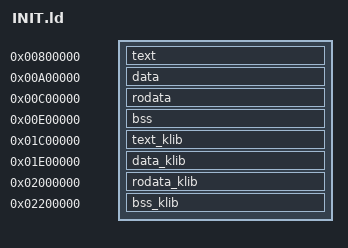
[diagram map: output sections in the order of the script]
/* 
 * File Generated by GEOS buildExec 
 * Copyright (c) 2023 DefinitelyNotAGirl@github 
 */
OUTPUT_FORMAT("binary")
ENTRY(init)
SECTIONS {
	. = 0x800000;
	text : {
		build/INIT/*.o (.text)
	}
	. = 0xA00000;
	data : {
		build/INIT/*.o (.data)
	}
	. = 0xC00000;
	rodata : {
		build/INIT/*.o (.rodata)
	}
	. = 0xE00000;
	bss : {
		build/INIT/*.o (.bss)
	}
	. = 0x1C00000;
	text_klib : {
		build/klib/*.o (.text)
	}
	. = 0x1E00000;
	data_klib : {
		build/klib/*.o (.data)
	}
	. = 0x2000000;
	rodata_klib : {
		build/klib/*.o (.rodata)
	}
	. = 0x2200000;
	bss_klib : {
		build/klib/*.o (.bss)
	}
	/DISCARD/ : {
		*(.note*)
		*(.iplt*)
		*(.igot*)
		*(.rel*)
		*(.comment*)
		*(.eh_frame*)
	}
}
